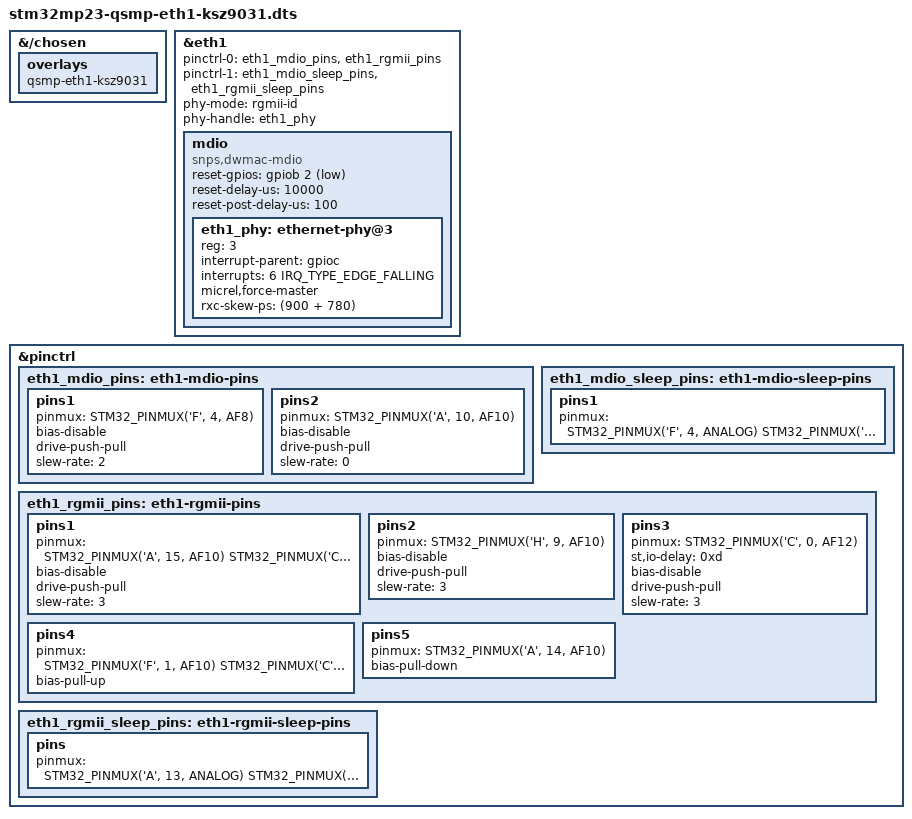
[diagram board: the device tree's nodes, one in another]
// SPDX-License-Identifier: (GPL-2.0-or-later OR BSD-2-Clause)
/*
 * Copyright (C) 2025 Marcel Mertens <MM@KARO-electronics.de>
 */

#include <dt-bindings/gpio/gpio.h>
#include <dt-bindings/interrupt-controller/irq.h>
#include <dt-bindings/pinctrl/stm32-pinfunc.h>

/dts-v1/;

/plugin/;

&{/chosen} {
	overlays {
		qsmp-eth1-ksz9031;
	};
};

&eth1 {
	pinctrl-names = "default", "sleep";
	pinctrl-0 = <&eth1_mdio_pins &eth1_rgmii_pins>;
	pinctrl-1 = <&eth1_mdio_sleep_pins &eth1_rgmii_sleep_pins>;
	phy-mode = "rgmii-id";
	phy-handle = <&eth1_phy>;
	status = "okay";

	mdio {
		compatible = "snps,dwmac-mdio";
		#address-cells = <1>;
		#size-cells = <0>;
		reset-gpios = <&gpiob 2 GPIO_ACTIVE_LOW>;
		reset-delay-us = <10000>;
		reset-post-delay-us = <100>;

		eth1_phy: ethernet-phy@3 {
			reg = <3>;
			interrupt-parent = <&gpioc>;
			interrupts = <6 IRQ_TYPE_EDGE_FALLING>;
			micrel,force-master;

			rxc-skew-ps = <(900 + 780)>;
		};
	};
};

&pinctrl {
	eth1_mdio_pins: eth1-mdio-pins {
		pins1 {
			pinmux = <STM32_PINMUX('F', 4, AF8)>;	/* ETH1_MDC */
			bias-disable;
			drive-push-pull;
			slew-rate = <2>;
		};

		pins2 {
			pinmux = <STM32_PINMUX('A', 10, AF10)>;	/* ETH1_MDIO */
			bias-disable;
			drive-push-pull;
			slew-rate = <0>;
		};
	};

	eth1_mdio_sleep_pins: eth1-mdio-sleep-pins {
		pins1 {
			pinmux = <
				  STM32_PINMUX('F', 4, ANALOG)	/* ETH1_MDC */
				  STM32_PINMUX('A', 10, ANALOG)	/* ETH1_MDIO */
			>;
		};
	};

	eth1_rgmii_pins: eth1-rgmii-pins {
		pins1 {
			pinmux = <
				  STM32_PINMUX('A', 15, AF10)	/* ETH1_TXD0 */
				  STM32_PINMUX('C', 1, AF10)	/* ETH1_TXD1 */
				  STM32_PINMUX('H', 10, AF10)	/* ETH1_TXD2 */
				  STM32_PINMUX('H', 11, AF10)	/* ETH1_TXD3 */
				  STM32_PINMUX('A', 13, AF10)	/* ETH1_TX_CTL */
			>;
			bias-disable;
			drive-push-pull;
			slew-rate = <3>;
		};

		pins2 {
			pinmux = <
				  STM32_PINMUX('H', 9, AF10)   /* ETH_RGMII_CLK125 */
			>;
			bias-disable;
			drive-push-pull;
			slew-rate = <3>;
		};

		pins3 {
			pinmux = <
				  STM32_PINMUX('C', 0, AF12)   /* ETH_RGMII_GTX_CLK */
			>;
			st,io-delay = <0xd>;
			bias-disable;
			drive-push-pull;
			slew-rate = <3>;
		};

		/* KSZ9031 strap pins */
		pins4 {
			pinmux = <
				  STM32_PINMUX('F', 1, AF10)	/* ETH1_RXD0 | MODE0 */
				  STM32_PINMUX('C', 2, AF10)	/* ETH1_RXD1 | MODE1 */
				  STM32_PINMUX('H', 12, AF10)	/* ETH1_RXD2 | MODE2 */
				  STM32_PINMUX('H', 13, AF10)	/* ETH1_RXD3 | MODE3 */
				  STM32_PINMUX('A', 11, AF10)	/* ETH1_RX_CTL | CLK125_EN */
			>;
			bias-pull-up;
		};

		pins5 {
			/* external pullup */
			pinmux = <
				  STM32_PINMUX('A', 14, AF10)	/* ETH1_RX_CLK | PHYAD2 */
			>;
			bias-pull-down;
		};
	};

	eth1_rgmii_sleep_pins: eth1-rgmii-sleep-pins {
		pins {
			pinmux = <
				  STM32_PINMUX('A', 13, ANALOG)	/* ETH1_TX_CTL */
				  STM32_PINMUX('C', 0, ANALOG)	/* ETH1_GTX_CLK */
				  STM32_PINMUX('A', 15, ANALOG)	/* ETH1_TXD0 */
				  STM32_PINMUX('C', 1, ANALOG)	/* ETH1_TXD1 */
				  STM32_PINMUX('H', 10, ANALOG)	/* ETH1_TXD2 */
				  STM32_PINMUX('H', 11, ANALOG)	/* ETH1_TXD3 */
				  STM32_PINMUX('A', 11, ANALOG)	/* ETH1_RX_CTL | CLK125_EN */
				  STM32_PINMUX('F', 1, ANALOG)	/* ETH1_RXD0 | MODE0 */
				  STM32_PINMUX('C', 2, ANALOG)	/* ETH1_RXD1 | MODE1 */
				  STM32_PINMUX('H', 12, ANALOG)	/* ETH1_RXD2 | MODE2 */
				  STM32_PINMUX('H', 13, ANALOG)	/* ETH1_RXD3 | MODE3 */
				  STM32_PINMUX('A', 14, ANALOG)	/* ETH1_RX_CLK | PHYAD2 */
			>;
		};
	};
};
